AUTOSAR XML (schema 4-2-2)
package /AUTOSAR/Components
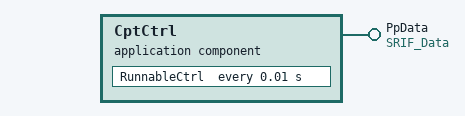
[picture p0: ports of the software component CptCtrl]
  application sw component type CptCtrl
    provide port PpData: provided-interface=SRIF_Data
    behavior IbCtrl
      timing event timingEvent_10: start-on-event=RunnableCtrl, period=0.01
      runnable RunnableCtrl: symbol=AppRunnableCtrl
        data-write-access:
          4 x access:
            dataWriteAccess_Primitive: accessed-variable=PpData.dataElementPrimitive
            dataWriteAccess_Array: accessed-variable=PpData.dataElementArray
            dataWriteAccess_Struct: accessed-variable=PpData.dataElementStruct
            dataWriteAccess_StructArray: accessed-variable=PpData.dataElementStructArray
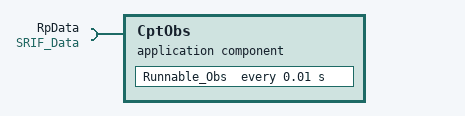
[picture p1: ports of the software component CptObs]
  application sw component type CptObs
    require port RpData: required-interface=SRIF_Data
      required-com-specs:
        data-element=dataElementPrimitive, external-replacement=dataElementPrimitive, init-value=0
        data-element=dataElementStruct, init-value=fields=[0, 1, 2]
        data-element=dataElementArray, init-value=[0]
        data-element=dataElementStructArray, init-value=fields=[0]
    behavior IbObs
      timing event timingEvent_10: start-on-event=Runnable_Obs, period=0.01
      runnable Runnable_Obs: symbol=AppRunnable_Obs
        data-read-access:
          4 x access:
            dataReadAccess_Primitive: accessed-variable=RpData.dataElementPrimitive
            dataReadAccess_Array: accessed-variable=RpData.dataElementArray
            dataReadAccess_Struct: accessed-variable=RpData.dataElementStruct
            dataReadAccess_StructArray: accessed-variable=RpData.dataElementStructArray
